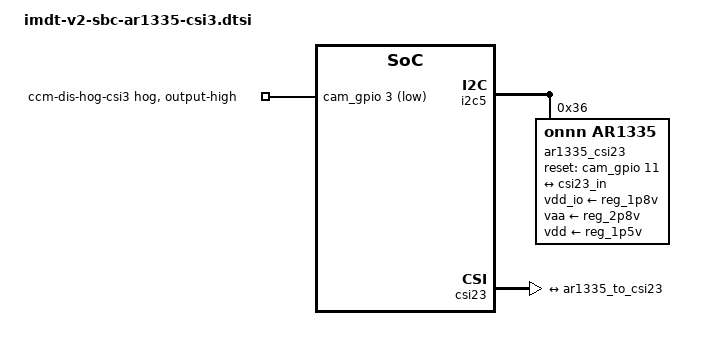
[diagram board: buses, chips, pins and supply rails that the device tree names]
&i2c5 {
	#address-cells = <1>;
	#size-cells = <0>;

	pinctrl-0 = <&i2c5_pins>;
	pinctrl-names = "default";

	status = "okay";

	ar1335_csi23: ar1335_csi23@36 {
		compatible = "onnn,ar1335";
		reg = <0x36>;
		clock-names = "extclk";
		clocks = <&clk_ext_camera>;
		vdd_io-supply = <&reg_1p8v>;
		vaa-supply = <&reg_2p8v>;
		vdd-supply = <&reg_1p5v>;
		

		reset-gpios = <&cam_gpio 11 GPIO_ACTIVE_HIGH>;//CCM2
		port {
			ar1335_to_csi23: endpoint {
				clock-lanes = <0>;
				data-lanes = <1 2 3 4>;
				remote-endpoint = <&csi23_in>;
			};
		};
	};
};
&csi23 {
    status = "okay";
    ports {
		#address-cells = <1>;
		#size-cells = <0>;

		port@0 {
			reg = <0>;
			csi23_in: endpoint {
				clock-lanes = <0>;
				data-lanes = <1 2 3 4>;
				remote-endpoint = <&ar1335_to_csi23>;
			};
		};
	};
};

&cam_gpio {
    ccm-dis-hog-csi3 {
			gpio-hog;
			gpios = <3 GPIO_ACTIVE_LOW>;
			output-high;
		};
	};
